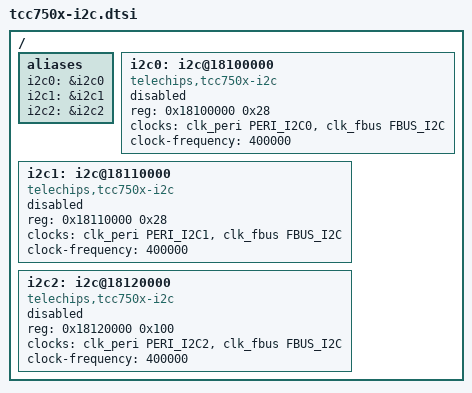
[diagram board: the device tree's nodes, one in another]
// SPDX-License-Identifier: (GPL-2.0-or-later OR MIT)
/*
 * Copyright (C) 2023 Telechips Inc.
 */

#include <dt-bindings/clock/telechips,tcc750x-clks.h>

/ {

	aliases: aliases {
		i2c0 = &i2c0;
		i2c1 = &i2c1;
		i2c2 = &i2c2;
	};

	i2c0: i2c@18100000 {
		compatible = "telechips,tcc750x-i2c";
		reg = <0x18100000 0x28>;
		#address-cells = <1>;
		#size-cells = <0>;
		clocks = <&clk_peri PERI_I2C0 &clk_fbus FBUS_I2C>;
		clock-frequency = <400000>;
		status = "disabled";
	};

	i2c1: i2c@18110000 {
		compatible = "telechips,tcc750x-i2c";
		reg = <0x18110000 0x28>;
		#address-cells = <1>;
		#size-cells = <0>;
		clocks = <&clk_peri PERI_I2C1 &clk_fbus FBUS_I2C>;
		clock-frequency = <400000>;
		status = "disabled";
	};

	i2c2: i2c@18120000 {
		compatible = "telechips,tcc750x-i2c";
		reg = <0x18120000 0x100>;
		#address-cells = <1>;
		#size-cells = <0>;
		clocks = <&clk_peri PERI_I2C2 &clk_fbus FBUS_I2C>;
		clock-frequency = <400000>;
		status = "disabled";
	};
};
